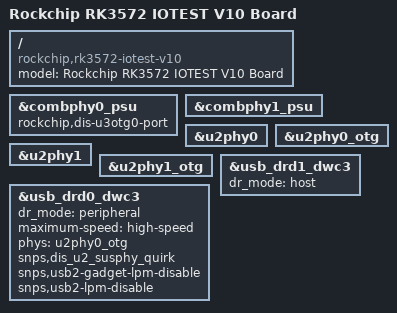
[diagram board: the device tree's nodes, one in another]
// SPDX-License-Identifier: (GPL-2.0+ OR MIT)
/*
 * Copyright (c) 2025 Rockchip Electronics Co., Ltd.
 */

/dts-v1/;

#include "rk3572-iotest-v10.dtsi"
#include "rk3572-android.dtsi"

/ {
	model = "Rockchip RK3572 IOTEST V10 Board";
	compatible = "rockchip,rk3572-iotest-v10", "rockchip,rk3572";
};

&combphy0_psu {
	rockchip,dis-u3otg0-port;
	status = "okay";
};

&combphy1_psu {
	status = "okay";
};

&u2phy0 {
	status = "okay";
};

&u2phy0_otg {
	status = "okay";
};

&u2phy1 {
	status = "okay";
};

&u2phy1_otg {
	status = "okay";
};

&usb_drd0_dwc3 {
	dr_mode = "peripheral";
	maximum-speed = "high-speed";
	phys = <&u2phy0_otg>;
	phy-names = "usb2-phy";
	snps,dis_u2_susphy_quirk;
	snps,usb2-gadget-lpm-disable;
	snps,usb2-lpm-disable;
	status = "okay";
};

&usb_drd1_dwc3 {
	dr_mode = "host";
	status = "okay";
};
